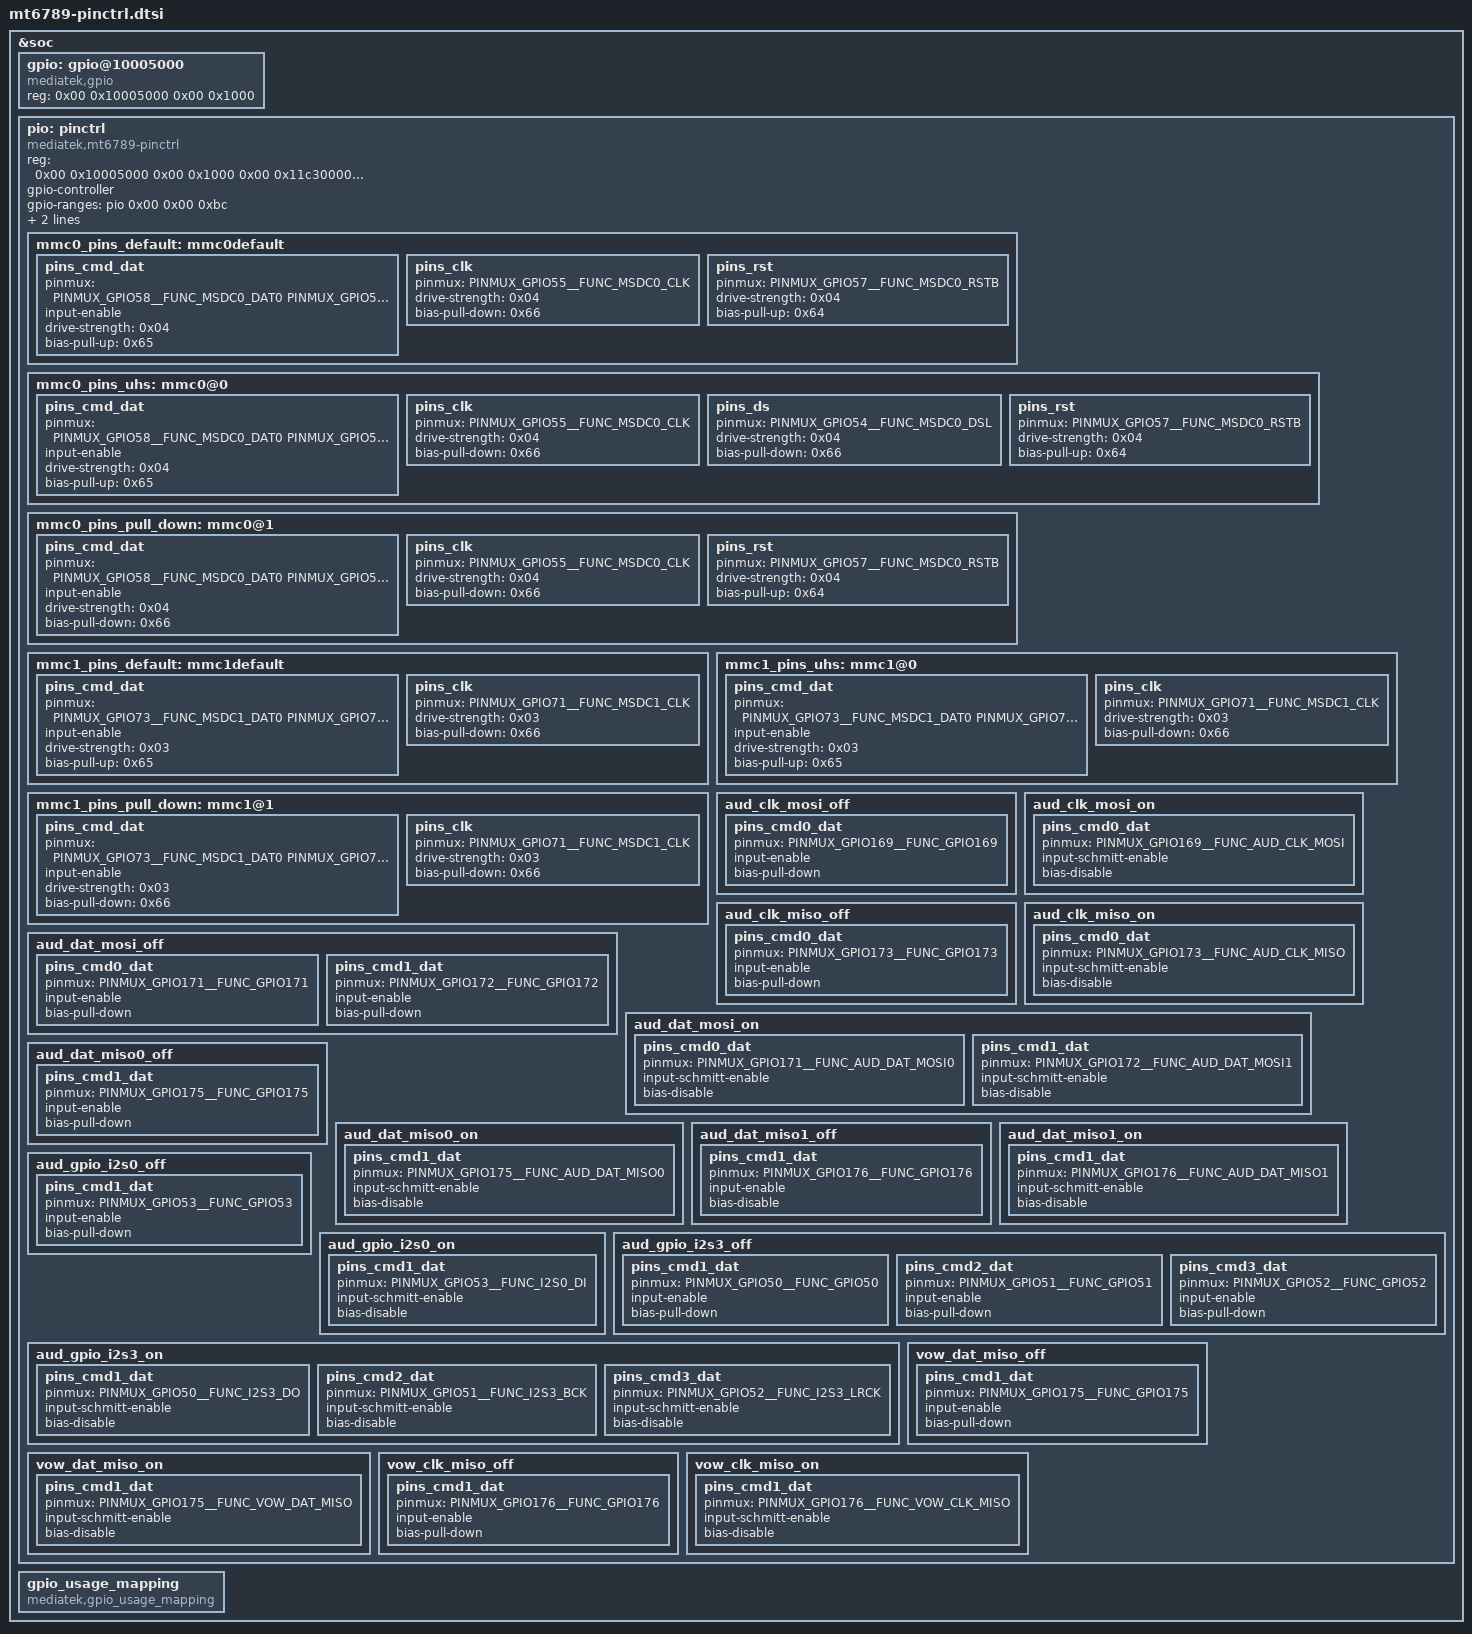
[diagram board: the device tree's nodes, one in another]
// SPDX-License-Identifier: (GPL-2.0 OR MIT)
/* MT6789 pinctrl blocks - split out of the soc node by tools/scripts/dts-socsplit.py */

&soc {
	gpio: gpio@10005000 {
		compatible = "mediatek,gpio";
		reg = <0x00 0x10005000 0x00 0x1000>;
	};

	pio: pinctrl {
		compatible = "mediatek,mt6789-pinctrl";
		reg = <0x00 0x10005000 0x00 0x1000 0x00 0x11c30000 0x00 0x1000 0x00 0x11d10000 0x00 0x1000 0x00 0x11d40000 0x00 0x1000 0x00 0x11e20000 0x00 0x1000 0x00 0x11e60000 0x00 0x1000 0x00 0x11ea0000 0x00 0x1000>;
		reg-names = "gpio", "iocfg_rb", "iocfg_bm", "iocfg_br", "iocfg_lm", "iocfg_bl", "iocfg_rt";
		gpio-controller;
		#gpio-cells = <0x02>;
		gpio-ranges = <&pio 0x00 0x00 0xbc>;
		interrupt-controller;
		#interrupt-cells = <0x02>;
		mediatek,eint = <&eint>;

		mmc0_pins_default: mmc0default {

			pins_cmd_dat {
				pinmux = <PINMUX_GPIO58__FUNC_MSDC0_DAT0 PINMUX_GPIO59__FUNC_MSDC0_DAT1 PINMUX_GPIO60__FUNC_MSDC0_DAT2 PINMUX_GPIO61__FUNC_MSDC0_DAT3 PINMUX_GPIO62__FUNC_MSDC0_DAT4 PINMUX_GPIO63__FUNC_MSDC0_DAT5 PINMUX_GPIO64__FUNC_MSDC0_DAT6 PINMUX_GPIO65__FUNC_MSDC0_DAT7 PINMUX_GPIO56__FUNC_MSDC0_CMD>;
				input-enable;
				drive-strength = <0x04>;
				bias-pull-up = <0x65>;
			};

			pins_clk {
				pinmux = <PINMUX_GPIO55__FUNC_MSDC0_CLK>;
				drive-strength = <0x04>;
				bias-pull-down = <0x66>;
			};

			pins_rst {
				pinmux = <PINMUX_GPIO57__FUNC_MSDC0_RSTB>;
				drive-strength = <0x04>;
				bias-pull-up = <0x64>;
			};
		};

		mmc0_pins_uhs: mmc0@0 {

			pins_cmd_dat {
				pinmux = <PINMUX_GPIO58__FUNC_MSDC0_DAT0 PINMUX_GPIO59__FUNC_MSDC0_DAT1 PINMUX_GPIO60__FUNC_MSDC0_DAT2 PINMUX_GPIO61__FUNC_MSDC0_DAT3 PINMUX_GPIO62__FUNC_MSDC0_DAT4 PINMUX_GPIO63__FUNC_MSDC0_DAT5 PINMUX_GPIO64__FUNC_MSDC0_DAT6 PINMUX_GPIO65__FUNC_MSDC0_DAT7 PINMUX_GPIO56__FUNC_MSDC0_CMD>;
				input-enable;
				drive-strength = <0x04>;
				bias-pull-up = <0x65>;
			};

			pins_clk {
				pinmux = <PINMUX_GPIO55__FUNC_MSDC0_CLK>;
				drive-strength = <0x04>;
				bias-pull-down = <0x66>;
			};

			pins_ds {
				pinmux = <PINMUX_GPIO54__FUNC_MSDC0_DSL>;
				drive-strength = <0x04>;
				bias-pull-down = <0x66>;
			};

			pins_rst {
				pinmux = <PINMUX_GPIO57__FUNC_MSDC0_RSTB>;
				drive-strength = <0x04>;
				bias-pull-up = <0x64>;
			};
		};

		mmc0_pins_pull_down: mmc0@1 {

			pins_cmd_dat {
				pinmux = <PINMUX_GPIO58__FUNC_MSDC0_DAT0 PINMUX_GPIO59__FUNC_MSDC0_DAT1 PINMUX_GPIO60__FUNC_MSDC0_DAT2 PINMUX_GPIO61__FUNC_MSDC0_DAT3 PINMUX_GPIO62__FUNC_MSDC0_DAT4 PINMUX_GPIO63__FUNC_MSDC0_DAT5 PINMUX_GPIO64__FUNC_MSDC0_DAT6 PINMUX_GPIO65__FUNC_MSDC0_DAT7 PINMUX_GPIO56__FUNC_MSDC0_CMD>;
				input-enable;
				drive-strength = <0x04>;
				bias-pull-down = <0x66>;
			};

			pins_clk {
				pinmux = <PINMUX_GPIO55__FUNC_MSDC0_CLK>;
				drive-strength = <0x04>;
				bias-pull-down = <0x66>;
			};

			pins_rst {
				pinmux = <PINMUX_GPIO57__FUNC_MSDC0_RSTB>;
				drive-strength = <0x04>;
				bias-pull-up = <0x64>;
			};
		};

		mmc1_pins_default: mmc1default {

			pins_cmd_dat {
				pinmux = <PINMUX_GPIO73__FUNC_MSDC1_DAT0 PINMUX_GPIO74__FUNC_MSDC1_DAT1 PINMUX_GPIO75__FUNC_MSDC1_DAT2 PINMUX_GPIO76__FUNC_MSDC1_DAT3 PINMUX_GPIO72__FUNC_MSDC1_CMD>;
				input-enable;
				drive-strength = <0x03>;
				bias-pull-up = <0x65>;
			};

			pins_clk {
				pinmux = <PINMUX_GPIO71__FUNC_MSDC1_CLK>;
				drive-strength = <0x03>;
				bias-pull-down = <0x66>;
			};
		};

		mmc1_pins_uhs: mmc1@0 {

			pins_cmd_dat {
				pinmux = <PINMUX_GPIO73__FUNC_MSDC1_DAT0 PINMUX_GPIO74__FUNC_MSDC1_DAT1 PINMUX_GPIO75__FUNC_MSDC1_DAT2 PINMUX_GPIO76__FUNC_MSDC1_DAT3 PINMUX_GPIO72__FUNC_MSDC1_CMD>;
				input-enable;
				drive-strength = <0x03>;
				bias-pull-up = <0x65>;
			};

			pins_clk {
				pinmux = <PINMUX_GPIO71__FUNC_MSDC1_CLK>;
				drive-strength = <0x03>;
				bias-pull-down = <0x66>;
			};
		};

		mmc1_pins_pull_down: mmc1@1 {

			pins_cmd_dat {
				pinmux = <PINMUX_GPIO73__FUNC_MSDC1_DAT0 PINMUX_GPIO74__FUNC_MSDC1_DAT1 PINMUX_GPIO75__FUNC_MSDC1_DAT2 PINMUX_GPIO76__FUNC_MSDC1_DAT3 PINMUX_GPIO72__FUNC_MSDC1_CMD>;
				input-enable;
				drive-strength = <0x03>;
				bias-pull-down = <0x66>;
			};

			pins_clk {
				pinmux = <PINMUX_GPIO71__FUNC_MSDC1_CLK>;
				drive-strength = <0x03>;
				bias-pull-down = <0x66>;
			};
		};

		aud_clk_mosi_off: aud_clk_mosi_off {

			pins_cmd0_dat {
				pinmux = <PINMUX_GPIO169__FUNC_GPIO169>;
				input-enable;
				bias-pull-down;
			};
		};

		aud_clk_mosi_on: aud_clk_mosi_on {

			pins_cmd0_dat {
				pinmux = <PINMUX_GPIO169__FUNC_AUD_CLK_MOSI>;
				input-schmitt-enable;
				bias-disable;
			};
		};

		aud_clk_miso_off: aud_clk_miso_off {

			pins_cmd0_dat {
				pinmux = <PINMUX_GPIO173__FUNC_GPIO173>;
				input-enable;
				bias-pull-down;
			};
		};

		aud_clk_miso_on: aud_clk_miso_on {

			pins_cmd0_dat {
				pinmux = <PINMUX_GPIO173__FUNC_AUD_CLK_MISO>;
				input-schmitt-enable;
				bias-disable;
			};
		};

		aud_dat_mosi_off: aud_dat_mosi_off {

			pins_cmd0_dat {
				pinmux = <PINMUX_GPIO171__FUNC_GPIO171>;
				input-enable;
				bias-pull-down;
			};

			pins_cmd1_dat {
				pinmux = <PINMUX_GPIO172__FUNC_GPIO172>;
				input-enable;
				bias-pull-down;
			};
		};

		aud_dat_mosi_on: aud_dat_mosi_on {

			pins_cmd0_dat {
				pinmux = <PINMUX_GPIO171__FUNC_AUD_DAT_MOSI0>;
				input-schmitt-enable;
				bias-disable;
			};

			pins_cmd1_dat {
				pinmux = <PINMUX_GPIO172__FUNC_AUD_DAT_MOSI1>;
				input-schmitt-enable;
				bias-disable;
			};
		};

		aud_dat_miso0_off: aud_dat_miso0_off {

			pins_cmd1_dat {
				pinmux = <PINMUX_GPIO175__FUNC_GPIO175>;
				input-enable;
				bias-pull-down;
			};
		};

		aud_dat_miso0_on: aud_dat_miso0_on {

			pins_cmd1_dat {
				pinmux = <PINMUX_GPIO175__FUNC_AUD_DAT_MISO0>;
				input-schmitt-enable;
				bias-disable;
			};
		};

		aud_dat_miso1_off: aud_dat_miso1_off {

			pins_cmd1_dat {
				pinmux = <PINMUX_GPIO176__FUNC_GPIO176>;
				input-enable;
				bias-disable;
			};
		};

		aud_dat_miso1_on: aud_dat_miso1_on {

			pins_cmd1_dat {
				pinmux = <PINMUX_GPIO176__FUNC_AUD_DAT_MISO1>;
				input-schmitt-enable;
				bias-disable;
			};
		};

		aud_gpio_i2s0_off: aud_gpio_i2s0_off {

			pins_cmd1_dat {
				pinmux = <PINMUX_GPIO53__FUNC_GPIO53>;
				input-enable;
				bias-pull-down;
			};
		};

		aud_gpio_i2s0_on: aud_gpio_i2s0_on {

			pins_cmd1_dat {
				pinmux = <PINMUX_GPIO53__FUNC_I2S0_DI>;
				input-schmitt-enable;
				bias-disable;
			};
		};

		aud_gpio_i2s3_off: aud_gpio_i2s3_off {

			pins_cmd1_dat {
				pinmux = <PINMUX_GPIO50__FUNC_GPIO50>;
				input-enable;
				bias-pull-down;
			};

			pins_cmd2_dat {
				pinmux = <PINMUX_GPIO51__FUNC_GPIO51>;
				input-enable;
				bias-pull-down;
			};

			pins_cmd3_dat {
				pinmux = <PINMUX_GPIO52__FUNC_GPIO52>;
				input-enable;
				bias-pull-down;
			};
		};

		aud_gpio_i2s3_on: aud_gpio_i2s3_on {

			pins_cmd1_dat {
				pinmux = <PINMUX_GPIO50__FUNC_I2S3_DO>;
				input-schmitt-enable;
				bias-disable;
			};

			pins_cmd2_dat {
				pinmux = <PINMUX_GPIO51__FUNC_I2S3_BCK>;
				input-schmitt-enable;
				bias-disable;
			};

			pins_cmd3_dat {
				pinmux = <PINMUX_GPIO52__FUNC_I2S3_LRCK>;
				input-schmitt-enable;
				bias-disable;
			};
		};

		vow_dat_miso_off: vow_dat_miso_off {

			pins_cmd1_dat {
				pinmux = <PINMUX_GPIO175__FUNC_GPIO175>;
				input-enable;
				bias-pull-down;
			};
		};

		vow_dat_miso_on: vow_dat_miso_on {

			pins_cmd1_dat {
				pinmux = <PINMUX_GPIO175__FUNC_VOW_DAT_MISO>;
				input-schmitt-enable;
				bias-disable;
			};
		};

		vow_clk_miso_off: vow_clk_miso_off {

			pins_cmd1_dat {
				pinmux = <PINMUX_GPIO176__FUNC_GPIO176>;
				input-enable;
				bias-pull-down;
			};
		};

		vow_clk_miso_on: vow_clk_miso_on {

			pins_cmd1_dat {
				pinmux = <PINMUX_GPIO176__FUNC_VOW_CLK_MISO>;
				input-schmitt-enable;
				bias-disable;
			};
		};
	};

	gpio_usage_mapping: gpio_usage_mapping {
		compatible = "mediatek,gpio_usage_mapping";
	};

};
